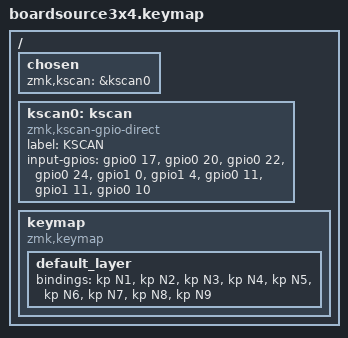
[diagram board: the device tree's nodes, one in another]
/*
 * Copyright (c) 2020 The ZMK Contributors
 *
 * SPDX-License-Identifier: MIT
 */

#include <behaviors.dtsi>
#include <dt-bindings/zmk/keys.h>
#include <dt-bindings/zmk/bt.h>

/ {
    chosen {
        zmk,kscan = &kscan0;
    };

    kscan0: kscan {
        compatible = "zmk,kscan-gpio-direct";
        label = "KSCAN";

        input-gpios = <
            &gpio0 17 (GPIO_ACTIVE_HIGH | GPIO_PULL_DOWN) // Tecla 1 (P0.17)
            &gpio0 20 (GPIO_ACTIVE_HIGH | GPIO_PULL_DOWN) // Tecla 2 (P0.20)
            &gpio0 22 (GPIO_ACTIVE_HIGH | GPIO_PULL_DOWN) // Tecla 3 (P0.22)
            &gpio0 24 (GPIO_ACTIVE_HIGH | GPIO_PULL_DOWN) // Tecla 4 (P0.24)
            &gpio1 0  (GPIO_ACTIVE_HIGH | GPIO_PULL_DOWN) // Tecla 5 (P1.00)
            &gpio1 4  (GPIO_ACTIVE_HIGH | GPIO_PULL_DOWN)  // Tecla 6 (P1.04)
            &gpio0 11 (GPIO_ACTIVE_HIGH | GPIO_PULL_DOWN)  // Tecla 7 (P0.11)
            &gpio1 11 (GPIO_ACTIVE_HIGH | GPIO_PULL_DOWN)  // Tecla 8 (P1.11)
            &gpio0 10 (GPIO_ACTIVE_HIGH | GPIO_PULL_DOWN)  // Tecla 9 (P0.10)
        >;
    };

    keymap {
        compatible = "zmk,keymap";

        default_layer {
            bindings = <
                &kp N1  // Tecla 1
                &kp N2  // Tecla 2
                &kp N3  // Tecla 3
                &kp N4  // Tecla 4
                &kp N5  // Tecla 5
                &kp N6  // Tecla 6
                &kp N7  // Tecla 7
                &kp N8  // Tecla 8
                &kp N9  // Tecla 9
            >;
        };
    };
};
